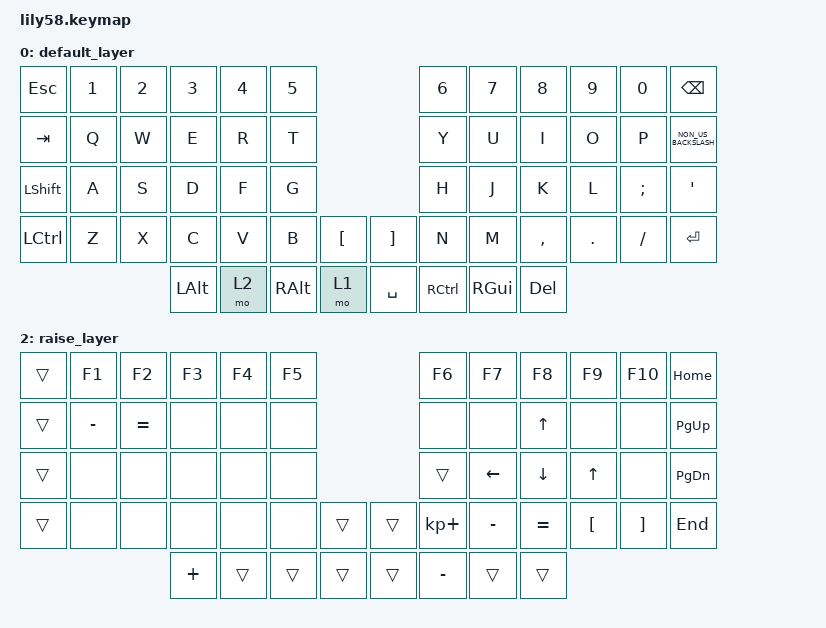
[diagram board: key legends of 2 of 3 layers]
/*
 * Copyright (c) 2020 The ZMK Contributors
 *
 * SPDX-License-Identifier: MIT
 */

#include <behaviors.dtsi>
#include <dt-bindings/zmk/bt.h>
#include <dt-bindings/zmk/keys.h>
#include <dt-bindings/zmk/pointing.h>
#include <dt-bindings/zmk/rgb.h>
#include <behaviors/mouse_keys.dtsi>

/ {
    // Add custom mouse configuration
    behaviors {
        msc_scrl_d: msc_scrl_d {
            compatible = "zmk,behavior-mouse-scroll";
            label = "MSC_SCRL_D";
            #binding-cells = <0>;
            delay-ms = <0>;
            time-to-max-speed-ms = <300>;
            acceleration-exponent = <1>;
            scroll-x = <0>;
            scroll-y = <(-15)>;  // Increased scroll speed (negative for down)
        };

        msc_scrl_u: msc_scrl_u {
            compatible = "zmk,behavior-mouse-scroll";
            label = "MSC_SCRL_U";
            #binding-cells = <0>;
            delay-ms = <0>;
            time-to-max-speed-ms = <300>;
            acceleration-exponent = <1>;
            scroll-x = <0>;
            scroll-y = <15>;  // Increased scroll speed (positive for up)
        };

        mmv_u: mmv_u {
            compatible = "zmk,behavior-mouse-move";
            label = "MMV_U";
            #binding-cells = <0>;
            delay-ms = <0>;
            time-to-max-speed-ms = <300>;
            acceleration-exponent = <1>;
            x-move = <0>;
            y-move = <(-20)>;  // Increased speed (negative for up)
        };

        mmv_d: mmv_d {
            compatible = "zmk,behavior-mouse-move";
            label = "MMV_D";
            #binding-cells = <0>;
            delay-ms = <0>;
            time-to-max-speed-ms = <300>;
            acceleration-exponent = <1>;
            x-move = <0>;
            y-move = <20>;  // Increased speed (positive for down)
        };

        mmv_l: mmv_l {
            compatible = "zmk,behavior-mouse-move";
            label = "MMV_L";
            #binding-cells = <0>;
            delay-ms = <0>;
            time-to-max-speed-ms = <300>;
            acceleration-exponent = <1>;
            x-move = <(-20)>;  // Increased speed (negative for left)
            y-move = <0>;
        };

        mmv_r: mmv_r {
            compatible = "zmk,behavior-mouse-move";
            label = "MMV_R";
            #binding-cells = <0>;
            delay-ms = <0>;
            time-to-max-speed-ms = <300>;
            acceleration-exponent = <1>;
            x-move = <20>;  // Increased speed (positive for right)
            y-move = <0>;
        };
    };

    keymap {
        compatible = "zmk,keymap";

        default_layer {
            // ------------------------------------------------------------------------------------------------------------
            // |  ESC  |  1  |  2  |  3   |  4   |  5   |                   |  6   |  7    |  8    |  9   |   0   |   `   |
            // |  TAB  |  Q  |  W  |  E   |  R   |  T   |                   |  Y   |  U    |  I    |  O   |   P   |   -   |
            // |  CTRL |  A  |  S  |  D   |  F   |  G   |                   |  H   |  J    |  K    |  L   |   ;   |   '   |
            // | SHIFT |  Z  |  X  |  C   |  V   |  B   |   "["  |  |  "]"  |  N   |  M    |  ,    |  .   |   /   | SHIFT |
            //                     | ALT  | GUI  | LOWER|  SPACE |  | ENTER | RAISE| BSPC  | GUI   |

            bindings = <
&kp ESC    &kp N1  &kp N2  &kp N3    &kp N4  &kp N5                                &kp N6             &kp N7         &kp N8      &kp N9   &kp N0    &kp BACKSPACE
&kp TAB    &kp Q   &kp W   &kp E     &kp R   &kp T                                 &kp Y              &kp U          &kp I       &kp O    &kp P     &kp NON_US_BACKSLASH
&kp LSHFT  &kp A   &kp S   &kp D     &kp F   &kp G                                 &kp H              &kp J          &kp K       &kp L    &kp SEMI  &kp SQT
&kp LCTRL  &kp Z   &kp X   &kp C     &kp V   &kp B          &kp LBKT    &kp RBKT   &kp N              &kp M          &kp COMMA   &kp DOT  &kp FSLH  &kp RET
                           &kp LALT  &mo 2   &kp RIGHT_ALT  &mo 1       &kp SPACE  &kp RIGHT_CONTROL  &kp RIGHT_GUI  &kp DELETE
            >;

            sensor-bindings = <&inc_dec_kp C_VOL_UP C_VOL_DN>;
        };

        lower_layer {
            // ------------------------------------------------------------------------------------------------------------
            // | BTCLR | BT1 | BT2 |  BT3 |  BT4 |  BT5 |                   |      |       |       |      |       |       |
            // |  F1   |  F2 |  F3 |  F4  |  F5  |  F6  |                   |  F7  |  F8   |  F9   |  F10 |  F11  |  F12  |
            // |   `   |  !  |  @  |  #   |  $   |  %   |                   |  ^   |  &    |  *    |  (   |   )   |   ~   |
            // |       |     |     |      |      |      |        |  |       |      |  _    |  +    |  {   |   }   |  "|"  |
            //                     |      |      |      |        |  |       |      |       |       |

bindings = <
    &bt  BT_CLR        &bt BT_SEL 0     &bt BT_SEL 1    &bt BT_SEL 2    &bt BT_SEL 3    &bt BT_SEL 4                    &trans &trans &none   &trans &trans &trans
    &kp  F11           &kp GRAVE        &kp SQT         &none           &none           &none                            &none  &none  &none  &mmv MOVE_UP  &none  &msc SCRL_UP
    &kp  F12           &kp EXCL         &kp AT          &kp HASH        &kp DOLLAR      &kp PRCNT                        &none  &mmv MOVE_LEFT    &mmv MOVE_DOWN       &mmv MOVE_RIGHT           &none            &none  &msc SCRL_DOWN
    &mkp LCLK          &rgb_ug RGB_TOG  &rgb_ug RGB_EFF &rgb_ug RGB_HUI &rgb_ug RGB_SAI &rgb_ug RGB_BRI   &trans &trans  &trans &kp MINUS &kp PLUS &kp LBRC &kp RBRC &none
                                       &mkp MCLK        &mkp RCLK       &trans          &trans            &trans &trans  &trans &trans
>;


            sensor-bindings = <&inc_dec_kp C_VOL_UP C_VOL_DN>;
        };

        raise_layer {
            // ------------------------------------------------------------------------------------------------------------
            // |       |     |     |      |      |      |                   |      |       |       |      |       |       |
            // |   `   |  1  |  2  |  3   |  4   |  5   |                   |  6   |   7   |   8   |  9   |   0   |       |
            // |   F1  |  F2 |  F3 |  F4  |  F5  |  F6  |                   |      |   <-  |   v   |  ^   |  ->   |       |
            // |   F7  |  F8 |  F9 |  F10 |  F11 |  F12 |        |  |       |  +   |   -   |   =   |  [   |   ]   |   \   |
            //                     |      |      |      |        |  |       |      |       |       |

            bindings = <
&trans  &kp F1     &kp F2     &kp F3    &kp F4  &kp F5                    &kp F6       &kp F7     &kp F8        &kp F9    &kp F10   &kp HOME
&trans  &kp MINUS  &kp EQUAL  &none     &none   &none                     &none        &none      &kp UP_ARROW  &none     &none     &kp PAGE_UP
&trans  &none      &none      &none     &none   &none                     &trans       &kp LEFT   &kp DOWN      &kp UP    &none     &kp PAGE_DOWN
&trans  &none      &none      &none     &none   &none   &trans    &trans  &kp KP_PLUS  &kp MINUS  &kp EQUAL     &kp LBKT  &kp RBKT  &kp END
                              &kp PLUS  &trans  &trans  &trans    &trans  &kp MINUS    &trans     &trans
            >;

            sensor-bindings = <&inc_dec_kp C_VOL_UP C_VOL_DN>;
        };
    };
};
